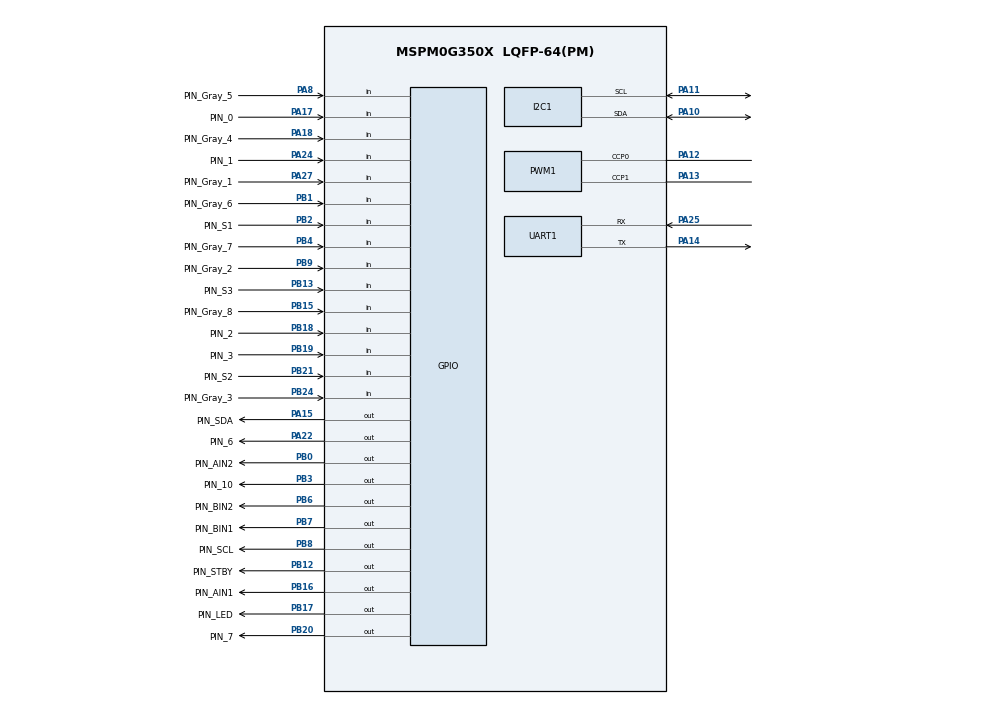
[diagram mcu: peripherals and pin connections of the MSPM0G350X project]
/**
 * @cliArgs --device "MSPM0G350X" --part "Default" --package "LQFP-64(PM)" --product "mspm0_sdk@2.05.00.05"
 * @versions {"tool":"1.27.1+4634"}
 */

/**
 * Import the modules used in this configuration.
 */
const Board  = scripting.addModule("/ti/driverlib/Board");
const GPIO   = scripting.addModule("/ti/driverlib/GPIO", {}, false);
const GPIO1  = GPIO.addInstance();
const GPIO2  = GPIO.addInstance();
const GPIO3  = GPIO.addInstance();
const GPIO4  = GPIO.addInstance();
const GPIO5  = GPIO.addInstance();
const GPIO6  = GPIO.addInstance();
const GPIO7  = GPIO.addInstance();
const GPIO8  = GPIO.addInstance();
const GPIO9  = GPIO.addInstance();
const GPIO10 = GPIO.addInstance();
const GPIO11 = GPIO.addInstance();
const I2C    = scripting.addModule("/ti/driverlib/I2C", {}, false);
const I2C1   = I2C.addInstance();
const PWM    = scripting.addModule("/ti/driverlib/PWM", {}, false);
const PWM1   = PWM.addInstance();
const SYSCTL = scripting.addModule("/ti/driverlib/SYSCTL");
const TIMER  = scripting.addModule("/ti/driverlib/TIMER", {}, false);
const TIMER1 = TIMER.addInstance();
const TIMER2 = TIMER.addInstance();
const UART   = scripting.addModule("/ti/driverlib/UART", {}, false);
const UART1  = UART.addInstance();

/**
 * Write custom configuration values to the imported modules.
 */
const divider7       = system.clockTree["PLL_PDIV"];
divider7.divideValue = 8;

const divider9       = system.clockTree["UDIV"];
divider9.divideValue = 2;

const multiplier2         = system.clockTree["PLL_QDIV"];
multiplier2.multiplyValue = 40;

const mux8       = system.clockTree["HSCLKMUX"];
mux8.inputSelect = "HSCLKMUX_SYSPLL0";


GPIO1.$name                         = "GPIO_EncoderA";
GPIO1.port                          = "PORTA";
GPIO1.associatedPins.create(2);
GPIO1.associatedPins[0].$name       = "PIN_0";
GPIO1.associatedPins[0].direction   = "INPUT";
GPIO1.associatedPins[0].interruptEn = true;
GPIO1.associatedPins[0].polarity    = "RISE";
GPIO1.associatedPins[0].pin.$assign = "PA17";
GPIO1.associatedPins[1].$name       = "PIN_1";
GPIO1.associatedPins[1].direction   = "INPUT";
GPIO1.associatedPins[1].interruptEn = true;
GPIO1.associatedPins[1].polarity    = "RISE";
GPIO1.associatedPins[1].pin.$assign = "PA24";

GPIO2.$name                         = "GPIO_EncoderB";
GPIO2.port                          = "PORTB";
GPIO2.associatedPins.create(2);
GPIO2.associatedPins[0].direction   = "INPUT";
GPIO2.associatedPins[0].interruptEn = true;
GPIO2.associatedPins[0].polarity    = "RISE";
GPIO2.associatedPins[0].$name       = "PIN_2";
GPIO2.associatedPins[0].pin.$assign = "PB18";
GPIO2.associatedPins[1].direction   = "INPUT";
GPIO2.associatedPins[1].interruptEn = true;
GPIO2.associatedPins[1].polarity    = "RISE";
GPIO2.associatedPins[1].$name       = "PIN_3";
GPIO2.associatedPins[1].pin.$assign = "PB19";

GPIO3.$name                         = "GPIO_IN";
GPIO3.associatedPins.create(4);
GPIO3.associatedPins[0].$name       = "PIN_AIN1";
GPIO3.associatedPins[0].pin.$assign = "PB16";
GPIO3.associatedPins[1].$name       = "PIN_AIN2";
GPIO3.associatedPins[1].pin.$assign = "PB0";
GPIO3.associatedPins[2].$name       = "PIN_BIN1";
GPIO3.associatedPins[2].pin.$assign = "PB7";
GPIO3.associatedPins[3].$name       = "PIN_BIN2";
GPIO3.associatedPins[3].pin.$assign = "PB6";

GPIO4.$name                         = "GPIO_Gray";
GPIO4.associatedPins.create(8);
GPIO4.associatedPins[0].direction   = "INPUT";
GPIO4.associatedPins[0].$name       = "PIN_Gray_1";
GPIO4.associatedPins[0].pin.$assign = "PA27";
GPIO4.associatedPins[1].$name       = "PIN_Gray_2";
GPIO4.associatedPins[1].direction   = "INPUT";
GPIO4.associatedPins[1].pin.$assign = "PB9";
GPIO4.associatedPins[2].$name       = "PIN_Gray_3";
GPIO4.associatedPins[2].direction   = "INPUT";
GPIO4.associatedPins[2].pin.$assign = "PB24";
GPIO4.associatedPins[3].$name       = "PIN_Gray_4";
GPIO4.associatedPins[3].direction   = "INPUT";
GPIO4.associatedPins[3].pin.$assign = "PA18";
GPIO4.associatedPins[4].$name       = "PIN_Gray_5";
GPIO4.associatedPins[4].direction   = "INPUT";
GPIO4.associatedPins[4].pin.$assign = "PA8";
GPIO4.associatedPins[5].$name       = "PIN_Gray_6";
GPIO4.associatedPins[5].direction   = "INPUT";
GPIO4.associatedPins[5].pin.$assign = "PB1";
GPIO4.associatedPins[6].$name       = "PIN_Gray_7";
GPIO4.associatedPins[6].direction   = "INPUT";
GPIO4.associatedPins[6].pin.$assign = "PB4";
GPIO4.associatedPins[7].$name       = "PIN_Gray_8";
GPIO4.associatedPins[7].direction   = "INPUT";
GPIO4.associatedPins[7].pin.$assign = "PB15";

GPIO5.$name                          = "GPIO_OLED";
GPIO5.associatedPins.create(2);
GPIO5.associatedPins[0].$name        = "PIN_SCL";
GPIO5.associatedPins[0].assignedPort = "PORTB";
GPIO5.associatedPins[0].assignedPin  = "8";
GPIO5.associatedPins[0].pin.$assign  = "PB8";
GPIO5.associatedPins[1].$name        = "PIN_SDA";
GPIO5.associatedPins[1].assignedPort = "PORTA";
GPIO5.associatedPins[1].assignedPin  = "15";
GPIO5.associatedPins[1].pin.$assign  = "PA15";

GPIO6.$name                              = "GPIO_Key";
GPIO6.associatedPins.create(3);
GPIO6.associatedPins[0].$name            = "PIN_S2";
GPIO6.associatedPins[0].direction        = "INPUT";
GPIO6.associatedPins[0].internalResistor = "PULL_UP";
GPIO6.associatedPins[0].pin.$assign      = "PB21";
GPIO6.associatedPins[1].$name            = "PIN_S1";
GPIO6.associatedPins[1].direction        = "INPUT";
GPIO6.associatedPins[1].internalResistor = "PULL_UP";
GPIO6.associatedPins[1].pin.$assign      = "PB2";
GPIO6.associatedPins[2].$name            = "PIN_S3";
GPIO6.associatedPins[2].direction        = "INPUT";
GPIO6.associatedPins[2].internalResistor = "PULL_UP";
GPIO6.associatedPins[2].pin.$assign      = "PB13";

GPIO7.$name                         = "GPIO_LED";
GPIO7.associatedPins[0].$name       = "PIN_LED";
GPIO7.associatedPins[0].pin.$assign = "PB17";

GPIO8.$name                         = "GPIO_STBY";
GPIO8.associatedPins[0].$name       = "PIN_STBY";
GPIO8.associatedPins[0].pin.$assign = "PB12";

GPIO9.$name                         = "GPIO_GIMBAL_PITCH_STEP";
GPIO9.associatedPins[0].$name       = "PIN_6";
GPIO9.associatedPins[0].pin.$assign = "PA22";

GPIO10.$name                         = "GPIO_GIMBAL_PITCH_DIR";
GPIO10.associatedPins[0].$name       = "PIN_7";
GPIO10.associatedPins[0].pin.$assign = "PB20";

GPIO11.$name                          = "GPIO_GIMBAL_PITCH_EN";
GPIO11.associatedPins[0].$name        = "PIN_10";
GPIO11.associatedPins[0].initialValue = "SET";
GPIO11.associatedPins[0].pin.$assign  = "PB3";

I2C1.basicEnableController             = true;
I2C1.intController                     = ["ARBITRATION_LOST","NACK","RXFIFO_TRIGGER","RX_DONE","TX_DONE"];
I2C1.$name                             = "I2C_Gray";
I2C1.peripheral.$assign                = "I2C1";
I2C1.peripheral.sdaPin.$assign         = "PA10";
I2C1.peripheral.sclPin.$assign         = "PA11";
I2C1.sdaPinConfig.hideOutputInversion  = scripting.forceWrite(false);
I2C1.sdaPinConfig.onlyInternalResistor = scripting.forceWrite(false);
I2C1.sdaPinConfig.passedPeripheralType = scripting.forceWrite("Digital");
I2C1.sdaPinConfig.$name                = "ti_driverlib_gpio_GPIOPinGeneric4";
I2C1.sclPinConfig.hideOutputInversion  = scripting.forceWrite(false);
I2C1.sclPinConfig.onlyInternalResistor = scripting.forceWrite(false);
I2C1.sclPinConfig.passedPeripheralType = scripting.forceWrite("Digital");
I2C1.sclPinConfig.$name                = "ti_driverlib_gpio_GPIOPinGeneric5";

PWM1.$name                      = "PWM_0";
PWM1.timerCount                 = 2500;
PWM1.peripheral.ccp0Pin.$assign = "PA12";
PWM1.peripheral.ccp1Pin.$assign = "PA13";
PWM1.PWM_CHANNEL_0.$name        = "ti_driverlib_pwm_PWMTimerCC0";
PWM1.PWM_CHANNEL_1.$name        = "ti_driverlib_pwm_PWMTimerCC1";
PWM1.ccp0PinConfig.$name        = "ti_driverlib_gpio_GPIOPinGeneric0";
PWM1.ccp1PinConfig.$name        = "ti_driverlib_gpio_GPIOPinGeneric1";

SYSCTL.forceDefaultClkConfig = true;
SYSCTL.clockTreeEn           = true;

TIMER1.$name              = "TIMER_Encoder_Read";
TIMER1.timerClkPrescale   = 256;
TIMER1.timerMode          = "PERIODIC";
TIMER1.interrupts         = ["ZERO"];
TIMER1.timerPeriod        = "10ms";
TIMER1.peripheral.$assign = "TIMG6";

TIMER2.timerClkPrescale   = 256;
TIMER2.timerMode          = "PERIODIC";
TIMER2.interrupts         = ["ZERO"];
TIMER2.$name              = "TIMER_GIMBAL";
TIMER2.timerPeriod        = "50us";
TIMER2.peripheral.$assign = "TIMG7";

UART1.$name                    = "UART_0";
UART1.targetBaudRate           = 115200;
UART1.enabledInterrupts        = ["RX"];
UART1.peripheral.rxPin.$assign = "PA25";
UART1.peripheral.txPin.$assign = "PA14";
UART1.txPinConfig.$name        = "ti_driverlib_gpio_GPIOPinGeneric2";
UART1.rxPinConfig.$name        = "ti_driverlib_gpio_GPIOPinGeneric3";

/**
 * Pinmux solution for unlocked pins/peripherals. This ensures that minor changes to the automatic solver in a future
 * version of the tool will not impact the pinmux you originally saw.  These lines can be completely deleted in order to
 * re-solve from scratch.
 */
Board.peripheral.$suggestSolution          = "DEBUGSS";
Board.peripheral.swclkPin.$suggestSolution = "PA20";
Board.peripheral.swdioPin.$suggestSolution = "PA19";
PWM1.peripheral.$suggestSolution           = "TIMG0";
UART1.peripheral.$suggestSolution          = "UART3";
